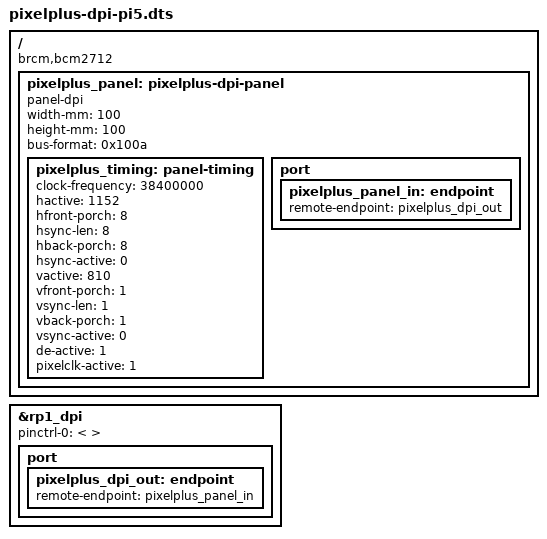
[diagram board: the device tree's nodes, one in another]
// SPDX-License-Identifier: GPL-3.0-or-later
/*
 * pixelplus-dpi-pi5 — DPI "panel" that turns the Raspberry Pi display pipeline
 * into a 24-bit parallel WS281x pixel engine (Raspberry Pi 5, 500, CM5 — RP1 DPI).
 * Original work for PixelPlus; see crates/pixelplus-output/DESIGN.md.
 *
 * Drives the RP1 southbridge's DPI block (the rp1-dpi DRM driver); the
 * Raspberry Pi OS default dtoverlay=vc4-kms-v3d stays in place for HDMI.
 * On RP1 the DPI pin function is alternate function a1 (a2 on older Pis).
 * Build and install:
 *
 *   dtc -@ -I dts -O dtb -o pixelplus-dpi-pi5.dtbo pixelplus-dpi-pi5.dts
 *   cp pixelplus-dpi-pi5.dtbo /boot/firmware/overlays/
 *
 * config.txt (generated by `pixelplus config-txt`):
 *
 *   dtoverlay=pixelplus-dpi-pi5,vactive=810
 *
 * The mode is 1152 active pixels per line at 38.4 MHz: 24 WS281x bits of
 * 48 pixels, i.e. one LED of every output per line. vactive = LEDs per output
 * plus the reset lines. Every timing parameter can be overridden.
 *
 * PIN MUXING: this overlay deliberately claims NO pins (pinctrl-0 is empty).
 * The DPI engine runs from boot, but its output only reaches the header once
 * pixelplusd switches exactly the board's pins to the DPI function
 * (difftx/diffsmart: GPIO4-7; difftxlarge: GPIO4-23 and GPIO25-27). Until then
 * — and after pixelplusd stops — the pins are plain GPIOs held low, so a boot
 * console or splash drawn into the DPI framebuffer never reaches the pixels,
 * and GPIO0-3 (ID EEPROM, I2C-1) and every unused GPIO stay free.
 */

/dts-v1/;
/plugin/;

/ {
	compatible = "brcm,bcm2712";

	fragment@0 {
		target-path = "/";
		__overlay__ {
			pixelplus_panel: pixelplus-dpi-panel {
				compatible = "panel-dpi";
				width-mm = <100>;
				height-mm = <100>;
				/* MEDIA_BUS_FMT_RGB888_1X24: framebuffer bit n -> DPI_Dn -> GPIO(n+4) */
				bus-format = <0x100a>;

				pixelplus_timing: panel-timing {
					clock-frequency = <38400000>;
					hactive = <1152>;
					hfront-porch = <8>;
					hsync-len = <8>;
					hback-porch = <8>;
					hsync-active = <0>;
					vactive = <810>;
					vfront-porch = <1>;
					vsync-len = <1>;
					vback-porch = <1>;
					vsync-active = <0>;
					de-active = <1>;
					pixelclk-active = <1>;
				};

				port {
					pixelplus_panel_in: endpoint {
						remote-endpoint = <&pixelplus_dpi_out>;
					};
				};
			};
		};
	};

	fragment@1 {
		target = <&rp1_dpi>;
		__overlay__ {
			status = "okay";
			pinctrl-names = "default";
			pinctrl-0 = < >;

			port {
				pixelplus_dpi_out: endpoint {
					remote-endpoint = <&pixelplus_panel_in>;
				};
			};
		};
	};

	__overrides__ {
		clock-frequency = <&pixelplus_timing>, "clock-frequency:0";
		hactive = <&pixelplus_timing>, "hactive:0";
		hfp = <&pixelplus_timing>, "hfront-porch:0";
		hsync = <&pixelplus_timing>, "hsync-len:0";
		hbp = <&pixelplus_timing>, "hback-porch:0";
		vactive = <&pixelplus_timing>, "vactive:0";
		vfp = <&pixelplus_timing>, "vfront-porch:0";
		vsync = <&pixelplus_timing>, "vsync-len:0";
		vbp = <&pixelplus_timing>, "vback-porch:0";
	};
};
